# alb32r003x register map
Vendor: ALB; Series: ALB RT SoC
CPU: ALB XF, little endian
Registers are 32-bit, access not given, reset 0x0 unless marked. A register's access mark holds for its fields unless they carry their own. Offsets are from the block's base; [hi:lo] are bit positions; {n}, {i} and the like mark numbered series.

## SDFM1
Base 0x21050000
Same registers: SDFM2 0x21050400
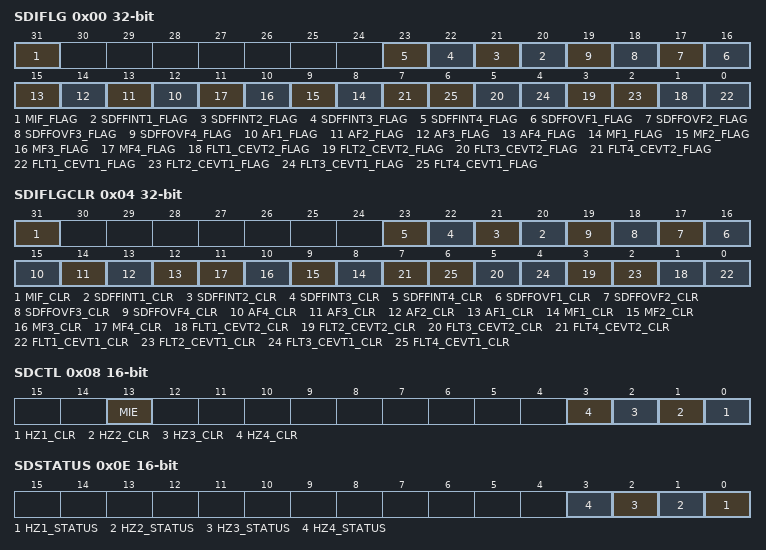
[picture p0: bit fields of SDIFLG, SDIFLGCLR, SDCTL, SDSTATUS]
0x00 SDIFLG
  [31] MIF_FLAG — Set whenever any "error" interrupt
  [n+19] SDFFINT{n}_FLAG (n=1..4) — SDFIFO data ready interrupt for Ch{n}
  [n+15] SDFFOVF{n}_FLAG (n=1..4) — FIFO Overflow Flag for Ch{n}
  [n+11] AF{n}_FLAG (n=1..4) — Acknowledge flag for Filter {n}
  [n+7] MF{n}_FLAG (n=1..4) — Modulator Failure for Filter {n}
  [2n-1] FLT{n}_CEVT2_FLAG (n=1..4) — CEVT2 Interrupt flag for filter{n}
  [2n-2] FLT{n}_CEVT1_FLAG (n=1..4) — CEVT1 Interrupt flag for filter{n}
0x04 SDIFLGCLR
  [31] MIF_CLR — Flag-clear bit for SDFM Master Interrupt flag.
  [n+19] SDFFINT{n}_CLR (n=1..4) — SDFIFO data ready Interrupt flag-clear bit for Ch{n}
  [n+15] SDFFOVF{n}_CLR (n=1..4) — SDFIFO overflow clear Ch{n}
  [15] AF4_CLR — Flag-clear bit for Acknowledge flag for Filter 4
  [14] AF3_CLR — Flag Clear bit for AF3
  [13] AF2_CLR — Flag Clear bit for AF2
  [12] AF1_CLR — Flag Clear bit for AF1
  [n+7] MF{n}_CLR (n=1..4) — Flag Clear bit for MF{n}
  [2n-1] FLT{n}_CEVT2_CLR (n=1..4) — Flag Clear bit for FLT{n} FLG CEVT2
  [2n-2] FLT{n}_CEVT1_CLR (n=1..4) — Flag Clear bit for FLT{n} FLG CEVT1
0x08 SDCTL 16-bit
  [13] MIE — Master SDy ERR interrupt enable
  [n-1] HZ{n}_CLR (n=1..4) — Flag Clear bit for HZ{n}
0x0C SDMFILEN 16-bit
  [11] MFE — Master Filter Enable
0x0E SDSTATUS 16-bit
  [n-1] HZ{n}_STATUS (n=1..4) — High-level Threshold crossing (Z) flag Ch{n}
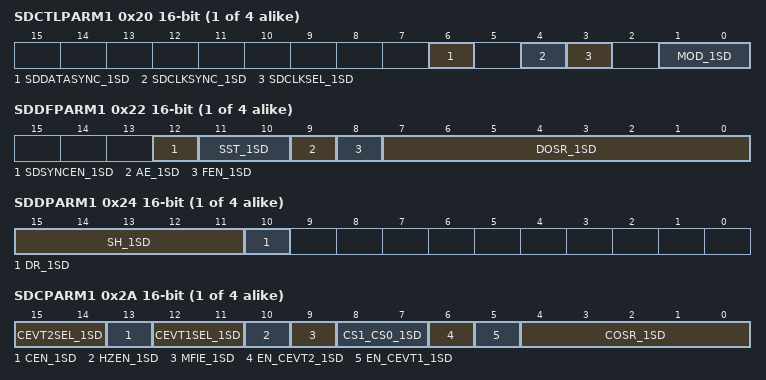
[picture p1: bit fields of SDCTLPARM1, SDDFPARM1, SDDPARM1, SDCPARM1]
{0x0+0x20*i} SDCTLPARM{i} 16-bit (i=1..4)
  [6] SDDATASYNC_{i}SD — 0: SD Data is not passed through a synchronizer.
  [4] SDCLKSYNC_{i}SD — 0: SD Clock is not passed through a synchronizer.
  [3] SDCLKSEL_{i}SD — SD{i} Clock source select.
  [1:0] MOD_{i}SD — Modulator clock modes
{0x2+0x20*i} SDDFPARM{i} 16-bit (i=1..4)
  [12] SDSYNCEN_{i}SD — PWM synchronization (SDSYNC) of data filter
  [11:10] SST_{i}SD — Data filter structure
  [9] AE_{i}SD — Data filter Acknowledge Enable
  [8] FEN_{i}SD — Filter Enable
  [7:0] DOSR_{i}SD — Data filter Oversampling ratio
{0x4+0x20*i} SDDPARM{i} 16-bit (i=1..4)
  [15:11] SH_{i}SD — Shift Control
  [10] DR_{i}SD — Data filter Data representation
{0x6+0x20*i} SDFLT{i}CMPH1 16-bit (i=1..4)
  [14:0] HLT_{i}SD — Unsigned high-level threshold for the comparator filter output.
{0x8+0x20*i} SDFLT{i}CMPL1 16-bit (i=1..4)
  [14:0] LLT_{i}SD — Unsigned low-level threshold for the comparator filter output.
{0xA+0x20*i} SDCPARM{i} 16-bit (i=1..4)
  [15:14] CEVT2SEL_{i}SD — Comparator Event2 Select
  [13] CEN_{i}SD — Comparator Filter enable
  [12:11] CEVT1SEL_{i}SD — Comparator Event1 Select
  [10] HZEN_{i}SD — High level (Z) Threshold crossing output enable
  [9] MFIE_{i}SD — Modulator Failure Interrupt Enable
  [8:7] CS1_CS0_{i}SD — Comparator fiter structure
  [6] EN_CEVT2_{i}SD — CEVT2 interrupt enable
  [5] EN_CEVT1_{i}SD — CEVT1 interrupt enable
  [4:0] COSR_{i}SD — Comparator Oversampling ratio.
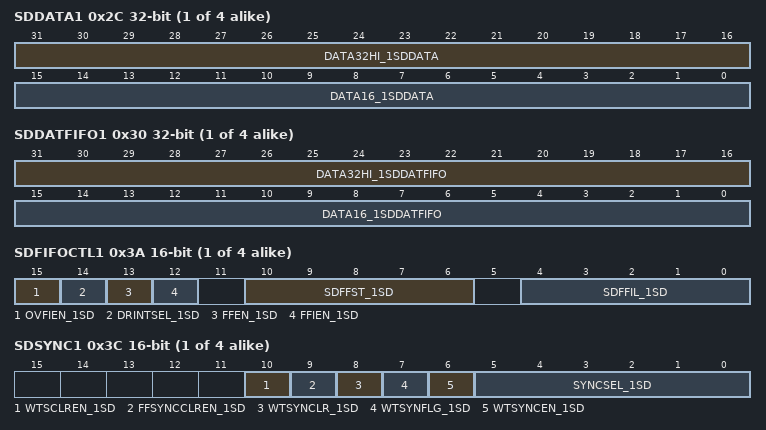
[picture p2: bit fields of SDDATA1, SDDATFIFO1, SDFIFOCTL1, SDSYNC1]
{0xC+0x20*i} SDDATA{i} (i=1..4)
  [31:16] DATA32HI_{i}SDDATA — Hi-order 16b in 32b mode, 16-bit Data in 16b mode
  [15:0] DATA16_{i}SDDATA — Lo-order 16b in 32b mode
{0x10+0x20*i} SDDATFIFO{i} (i=1..4)
  [31:16] DATA32HI_{i}SDDATFIFO — Hi-order 16b in 32b mode, 16-bit Data in 16b mode
  [15:0] DATA16_{i}SDDATFIFO — Lo-order 16b in 32b mode
{0x14+0x20*i} SDCDATA{i} 16-bit (i=1..4)
  [15:0] DATA16_{i}SDCDATA — Comparator Data output - 16b only
0x36 SDFLT1CMPH2 16-bit
  [14:0] HLT2_1SD — Second Unsigned high-level threshold for the comparator filter
0x38 SDFLT1CMPHZ 16-bit
  [14:0] HLTZ_1SD — Unsigned High-level threshold (Z) for the comparator fiter output
{0x1A+0x20*i} SDFIFOCTL{i} 16-bit (i=1..4)
  [15] OVFIEN_{i}SD — SDFIFO Overflow interrupt enable
  [14] DRINTSEL_{i}SD — Data-Ready Interrupt (DRINT) source select
  [13] FFEN_{i}SD — SDFIFO Enable
  [12] FFIEN_{i}SD — SDFIFO data ready Interrupt Enable
  [10:6] SDFFST_{i}SD — SDFIFO Status
  [4:0] SDFFIL_{i}SD — SDFIFO interrupt level bits
{0x1C+0x20*i} SDSYNC{i} 16-bit (i=1..4)
  [10] WTSCLREN_{i}SD — WTSYNFLG Clear-on-FIFOINT Enable
  [9] FFSYNCCLREN_{i}SD — FIFO Clear-on-SDSYNC Enable
  [8] WTSYNCLR_{i}SD — Wait-for-Sync Flag Clear (always reads 0)
  [7] WTSYNFLG_{i}SD — Wait-for-Sync Flag
  [6] WTSYNCEN_{i}SD — Wait-for-Sync Enable
  [5:0] SYNCSEL_{i}SD — Defines source for the SDSYNC Input on this channel
{0x1E+0x20*i} SDFLT{i}CMPL2 16-bit (i=1..3)
  [14:0] LLT2_{i}SD — Second Unsigned low-level threshold for the comparator filter output.
0x56 SDFLT2CMPH2 16-bit
  [14:0] HLT2_2SD — Second Unsigned high-level threshold for the comparator fiter
0x58 SDFLT2CMPHZ 16-bit
  [14:0] HLTZ_2SD — Unsigned High-level threshold (Z) for the comparator filter output
0x76 SDFLT3CMPH2 16-bit
  [14:0] HLT2_3SD — Second Unsigned high-level threshold for the comparator filter
0x78 SDFLT3CMPHZ 16-bit
  [14:0] HLTZ_3SD — Unsigned High-level threshold (Z) for the comparator fiter output
0x96 SDFLT4CMPH2 16-bit
  [14:0] HLT2_4SD — Second Unsigned high-level threshold for the comparator fiter
0x98 SDFLT4CMPHZ 16-bit
  [14:0] HLTZ_4SD — Unsigned High-level threshold (Z) for the comparator filter output
